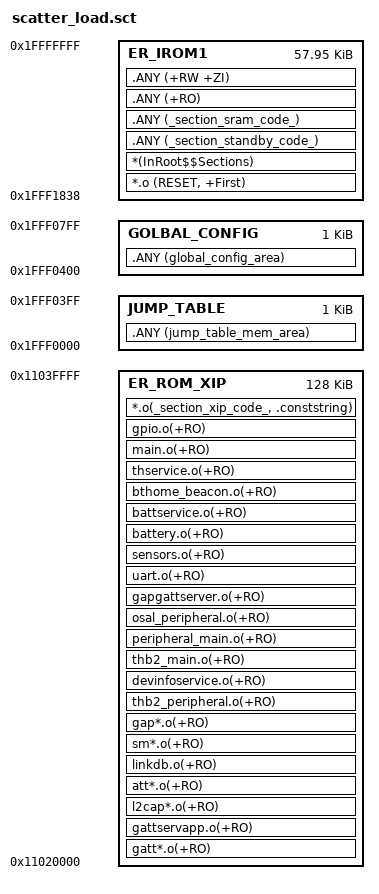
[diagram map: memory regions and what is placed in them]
; *************************************************************
; *** Scatter-Loading Description File generated by uVision ***
; *************************************************************

LR_IROM1 0x1fff1838 0x0E7C8 {  ; load region size_region
 ER_IROM1 0x1fff1838 0x0E7C8  {  ; load address = execution address
;LR_IROM1 0x1fff1838 0x067C8 {  ; load region size_region
; ER_IROM1 0x1fff1838 0x067C8  {  ; load address = execution address
  *.o (RESET, +First)
  *(InRoot$$Sections)
  .ANY (_section_standby_code_)
  .ANY (_section_sram_code_)
  ;*.o(_section_standby_code_)
  ;*.o(_section_sram_code_)
  .ANY (+RO)  
  .ANY (+RW +ZI)
 }
;  ER_IROM2 0x1fffc000 0x04000  {  ; load address = execution address
;;  rf_phy_driver.o(i.rf_phy_dtm*)
;;  rf_phy_driver.o(i.rf_phy_direct_*)
; }
}
LR_ROM_JT_GC  0x1fff0000 0x00800 {
  JUMP_TABLE 0x1fff0000 0x00400  {
   .ANY (jump_table_mem_area) 
	
  }
  GOLBAL_CONFIG 0x1fff0400 0x00400  {
   .ANY (global_config_area) 
	
  }  
 } 
LR_ROM_XIP  0x11020000 0x020000 {
  ER_ROM_XIP 0x11020000 0x020000  {  ; load address = execution address
   gatt*.o(+RO)
   gattservapp.o(+RO)
   l2cap*.o(+RO)
   att*.o(+RO)
   linkdb.o(+RO)
   sm*.o(+RO)
   gap*.o(+RO)
   thb2_peripheral.o(+RO)
   ;battservice.o(+RO)
   devinfoservice.o(+RO)
   thb2_main.o(+RO)
   peripheral_main.o(+RO)
   osal_peripheral.o(+RO)
   gapgattserver.o(+RO) 
   ;gapbondmgr.o(+RO) 
   uart.o(+RO)
   sensors.o(+RO)
   battery.o(+RO)
   battservice.o(+RO)
;   i2c.o(+RO)
   bthome_beacon.o(+RO)
   thservice.o(+RO)
   main.o(+RO)
;   ota_app_service.o(+RO)
;   my_printf.o(+RO)
   gpio.o(+RO)
   ;osal_snv.o(+RO)
   *.o(_section_xip_code_, .conststring)
  }
 }  



